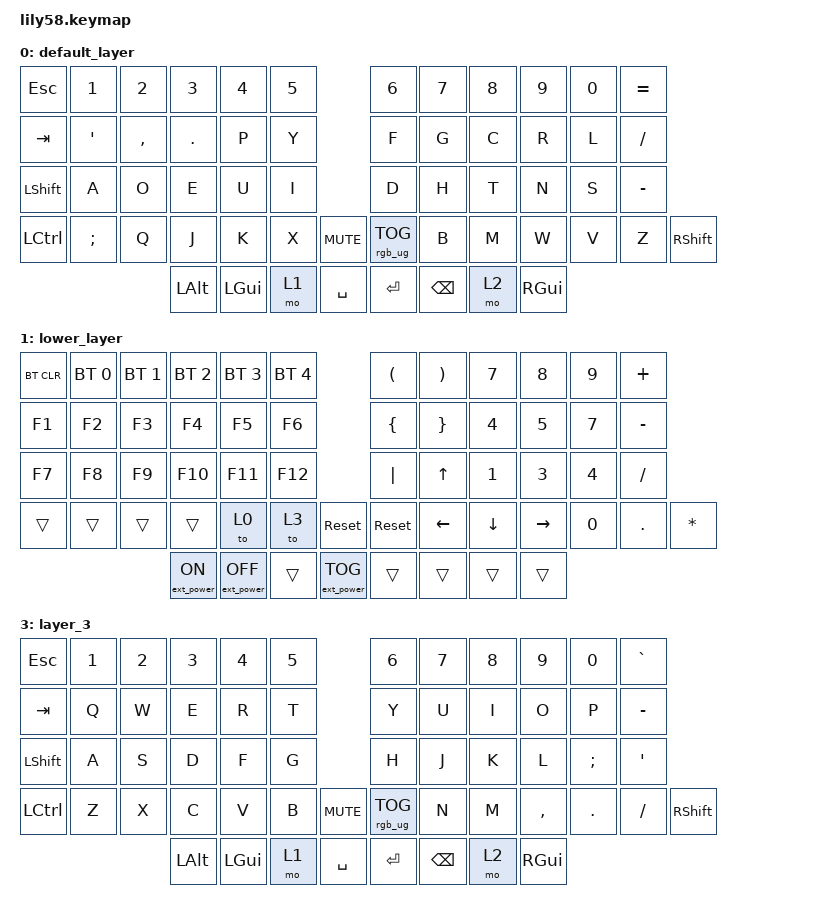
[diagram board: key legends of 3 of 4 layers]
/*
 * Copyright (c) 2020 The ZMK Contributors
 *
 * SPDX-License-Identifier: MIT
 */
#define ZMK_POINTING_DEFAULT_SCRL_VAL 140    // default: 10


#include <behaviors.dtsi>
#include <dt-bindings/zmk/keys.h>
#include <dt-bindings/zmk/bt.h>
#include <dt-bindings/zmk/ext_power.h>
#include <dt-bindings/zmk/rgb.h>
#include <dt-bindings/zmk/pointing.h>
/ {

    scroll_up_down: behavior_sensor_rotate_mouse_wheel_up_down {
        compatible = "zmk,behavior-sensor-rotate";
        #sensor-binding-cells = <0>;
        tap-ms = <20>;
        bindings = <&msc SCRL_UP>, <&msc SCRL_DOWN>;
    };

    zoom_in_out: behavior_sensor_rotate_zoom_in_out {
        compatible = "zmk,behavior-sensor-rotate";
        #sensor-binding-cells = <0>;
        bindings = <&kp LC(MINUS)>, <&kp LC(PLUS)>;
    };
        // Activate ADJUST layer by pressing raise and lower
    keymap {
        compatible = "zmk,keymap";

        default_layer {
// ------------------------------------------------------------------------------------------------------------
// |  ESC  |  1  |  2  |  3   |  4   |  5   |                   |  6   |  7    |  8    |  9   |   0   |   +   |
// |  TAB  |  '  |  ,  |  .   |  P   |  Y   |                   |  F   |  G    |  C    |  R   |   L   |   /   |
// |  SHIFT|  A  |  O  |  E   |  U   |  I   |                   |  D   |  H    |  T    |  N   |   S   |   -   |
// | CTRL |   ;  |  Q  |  J   |  K   |  X   |  MUTE  |  |RGB_TOG|  B   |  M    |  W    |  V   |   Z   | SHIFT |
//                     | ALT  | GUI  | LOWER|  SPACE |  | ENTER | BSPC| RAISE  | GUI   |
            bindings = <
&kp ESC   &kp N1 &kp N2 &kp N3   &kp N4   &kp N5                     &kp N6 &kp N7   &kp N8    &kp N9  &kp N0   &kp EQUAL
&kp TAB   &kp SQT  &kp COMMA  &kp DOT    &kp P    &kp Y                      &kp F  &kp G    &kp C     &kp R   &kp L    &kp FSLH
&kp LSHFT &kp A  &kp O  &kp E    &kp U    &kp I                      &kp D  &kp H    &kp T     &kp N   &kp S &kp MINUS
&kp LCTRL &kp SEMI  &kp Q  &kp J    &kp K    &kp X  &kp C_MUTE   &rgb_ug RGB_TOG  &kp B  &kp M    &kp W &kp V &kp Z &kp RSHFT
                        &kp LALT &kp LGUI &mo 1  &kp SPACE  &kp RET  &kp BSPC  &mo 2 &kp RGUI
            >;
                    sensor-bindings = <&inc_dec_kp C_VOL_UP C_VOL_DN &scroll_up_down>;
        };

        lower_layer {
// ------------------------------------------------------------------------------------------------------------
// | BTCLR | BT1 | BT2 |  BT3 |  BT4 |  BT5 |                   |  (   |  )    |   7   |  8   |   9   |   +   |
// |  F1   |  F2 |  F3 |  F4  |  F5  |  F6  |                   |  {   |  }    |   4   |  5   |   6   |   -   |
// |  F7   |  F8 | F9  | F10  |  F11 | F12  |                   |  |   |   UP  |   1   |  2   |   3   |   /   |
// |       |     |     |      |      |      | RESET  |  | RESET |LEFT  | DOWN  | RIGHT |  0   |   .   |   *   |
//                     |EXTON |EXTOFF|      | EXTTOG |  |       |      |       |       |
            bindings = <
&bt BT_CLR &bt BT_SEL 0     &bt BT_SEL 1      &bt BT_SEL 2      &bt BT_SEL 3 &bt BT_SEL 4                     &kp LPAR  &kp RPAR  &kp   N7  &kp   N8 &kp   N9  &kp PLUS
&kp F1     &kp F2           &kp F3            &kp F4            &kp F5       &kp F6                           &kp LBRC  &kp RBRC  &kp   N4  &kp   N5 &kp   N7  &kp MINUS
&kp F7     &kp F8           &kp F9            &kp F10           &kp F11      &kp F12                          &kp PIPE  &kp UP    &kp   N1  &kp   N3 &kp   N4  &kp SLASH
&trans     &trans           &trans            &trans            &to 0       &to 3   &sys_reset  &sys_reset  &kp LEFT  &kp DOWN  &kp RIGHT &kp  N0  &kp DOT   &kp STAR
                                &ext_power EP_ON &ext_power EP_OFF &trans &ext_power EP_TOG       &trans      &trans    &trans    &trans
            >;

             sensor-bindings = <&inc_dec_kp RIGHT LEFT &zoom_in_out>;
        };

        adjust_layer {
// ----------------------------------------------------------------------------------------------------------------------------
// | BTCLR  |  BT1    |  BT2    |   BT3   |   BT4   |   BT5   |                  |      |      |       |      |       |       |
// | EXTPWR | RGB_HUD | RGB_HUI | RGB_SAD | RGB_SAI | RGB_EFF |                  |      |      |       |      |       |       |
// |        | RGB_BRD | RGB_BRI |         |         |         |                  |      |      |       |      |       |       |
// |        |         |         |         |         |         | RGB_TOG | |      |      |      |       |      |       |       |
//                    |         |         |         |         |         | |      |      |      |       |      |
            bindings = <
&bt BT_CLR        &bt BT_SEL 0    &bt BT_SEL 1    &bt BT_SEL 2    &bt BT_SEL 3    &bt BT_SEL 4                            &trans &trans &trans &trans &trans &trans
&ext_power EP_TOG &rgb_ug RGB_HUD &rgb_ug RGB_HUI &rgb_ug RGB_SAD &rgb_ug RGB_SAI &rgb_ug RGB_EFF                         &trans &trans &trans &trans &trans &trans
&trans             &rgb_ug RGB_BRD &rgb_ug RGB_BRI &trans           &trans           &trans                                   &trans &trans &trans &trans &trans &trans
&trans             &trans           &trans           &trans           &trans           &trans            &trans &trans  &trans &trans &trans &trans &trans &trans
                                  &trans           &trans           &trans           &trans            &trans           &trans  &trans &trans &trans &trans
            >;
            sensor-bindings = <&inc_dec_kp C_VOL_UP C_VOL_DN>;
        };
        
        layer_3 {
// ------------------------------------------------------------------------------------------------------------
// |  ESC  |  1  |  2  |  3   |  4   |  5   |                   |  6   |  7    |  8    |  9   |   0   |   `   |
// |  TAB  |  Q  |  W  |  E   |  R   |  T   |                   |  Y   |  U    |  I    |  O   |   P   |   -   |
// |  SHIFT|  A  |  S  |  D   |  F   |  G   |                   |  H   |  J    |  K    |  L   |   ;   |   '   |
// | CTRL |  Z  |  X  |  C   |  V   |  B   |  MUTE  |  |RGB_TOG|  N   |  M    |  ,    |  .   |   /   | SHIFT |
//                     | ALT  | GUI  | LOWER|  SPACE |  | ENTER | BSPC| RAISE  | GUI   |
            bindings = <
&kp ESC   &kp N1 &kp N2 &kp N3   &kp N4   &kp N5                     &kp N6 &kp N7   &kp N8    &kp N9  &kp N0   &kp GRAVE
&kp TAB   &kp Q  &kp W  &kp E    &kp R    &kp T                      &kp Y  &kp U    &kp I     &kp O   &kp P    &kp MINUS
&kp LSHFT &kp A  &kp S  &kp D    &kp F    &kp G                      &kp H  &kp J    &kp K     &kp L   &kp SEMI &kp SQT
&kp LCTRL &kp Z  &kp X  &kp C    &kp V    &kp B  &kp C_MUTE   &rgb_ug RGB_TOG  &kp N  &kp M    &kp COMMA &kp DOT &kp FSLH &kp RSHFT
                        &kp LALT &kp LGUI &mo 1  &kp SPACE  &kp RET  &kp BSPC  &mo 2 &kp RGUI
            >;

            sensor-bindings = <&inc_dec_kp C_VOL_UP C_VOL_DN &scroll_up_down>;
                };
//         extra1 { status = "reserved"; };
//
  //      extra2 { status = "reserved"; };
//
  //      extra3 { status = "reserved"; };
//
  //      extra4 { status = "reserved"; };
//
  //      extra5 { status = "reserved"; };
    };
};
